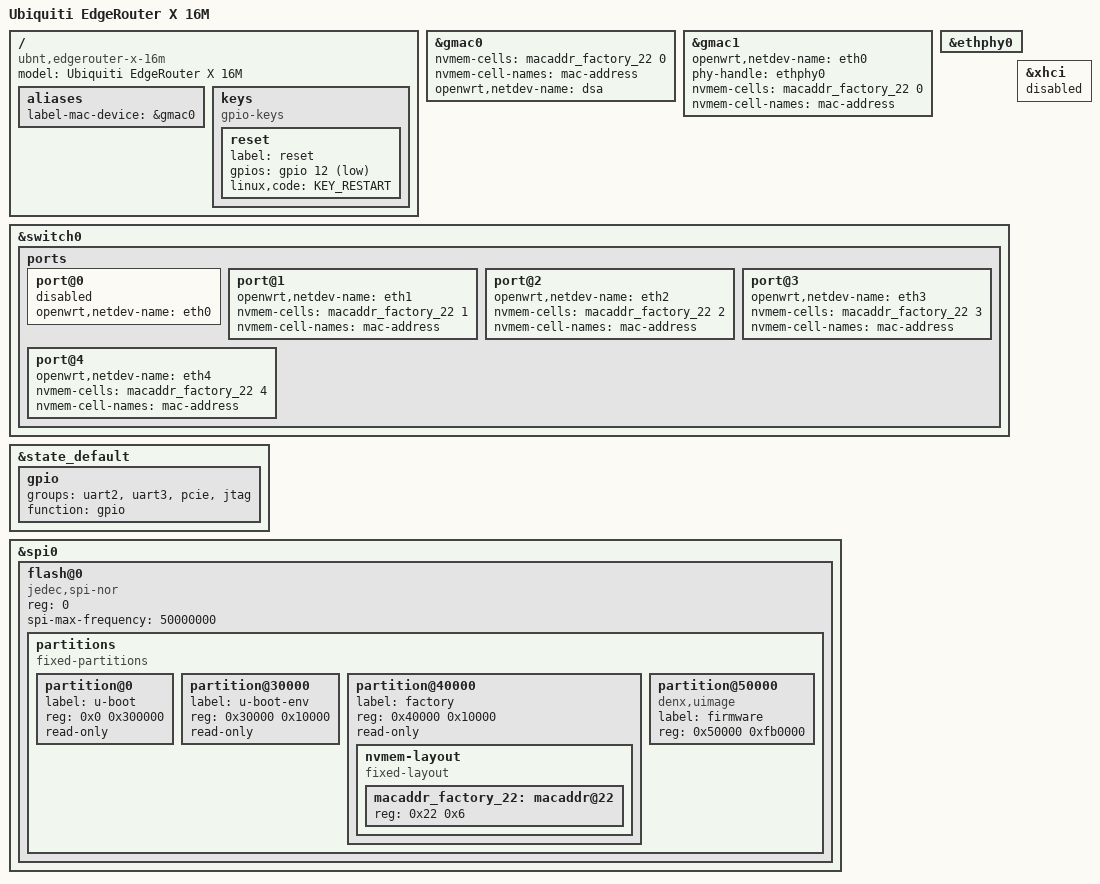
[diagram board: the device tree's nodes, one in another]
#include "mt7621.dtsi"

#include <dt-bindings/gpio/gpio.h>
#include <dt-bindings/input/input.h>

/ {
	model = "Ubiquiti EdgeRouter X 16M";
	compatible = "ubnt,edgerouter-x-16m", "mediatek,mt7621-soc";
};

/ {
	aliases {
		label-mac-device = &gmac0;
	};

	keys {
		compatible = "gpio-keys";

		reset {
			label = "reset";
			gpios = <&gpio 12 GPIO_ACTIVE_LOW>;
			linux,code = <KEY_RESTART>;
		};
	};
};

&gmac0 {
	nvmem-cells = <&macaddr_factory_22 0>;
	nvmem-cell-names = "mac-address";
	openwrt,netdev-name = "dsa";
};

&gmac1 {
	status = "okay";
	openwrt,netdev-name = "eth0";
	phy-handle = <&ethphy0>;

	nvmem-cells = <&macaddr_factory_22 0>;
	nvmem-cell-names = "mac-address";
};

&ethphy0 {
	/delete-property/ interrupts;
};

&switch0 {
	ports {
		port@0 {
			status = "disabled";
			openwrt,netdev-name = "eth0";
			/delete-property/ label;
		};

		port@1 {
			status = "okay";
			openwrt,netdev-name = "eth1";
			nvmem-cells = <&macaddr_factory_22 1>;
			nvmem-cell-names = "mac-address";
			/delete-property/ label;
		};

		port@2 {
			status = "okay";
			openwrt,netdev-name = "eth2";
			nvmem-cells = <&macaddr_factory_22 2>;
			nvmem-cell-names = "mac-address";
			/delete-property/ label;
		};

		port@3 {
			status = "okay";
			openwrt,netdev-name = "eth3";
			nvmem-cells = <&macaddr_factory_22 3>;
			nvmem-cell-names = "mac-address";
			/delete-property/ label;
		};

		port@4 {
			status = "okay";
			openwrt,netdev-name = "eth4";
			nvmem-cells = <&macaddr_factory_22 4>;
			nvmem-cell-names = "mac-address";
			/delete-property/ label;
		};
	};
};

&state_default {
	gpio {
		groups = "uart2", "uart3", "pcie", "jtag";
		function = "gpio";
	};
};

&spi0 {
	status = "okay";

	flash@0 {
		compatible = "jedec,spi-nor";
		reg = <0>;
		spi-max-frequency = <50000000>;

		partitions {
			compatible = "fixed-partitions";
			#address-cells = <1>;
			#size-cells = <1>;

			partition@0 {
				label = "u-boot";
				reg = <0x0 0x300000>;
				read-only;
			};
			
			partition@30000 {
				label = "u-boot-env";
				reg = <0x30000 0x10000>;
				read-only;
			};
			
			partition@40000 {
				label = "factory";
				reg = <0x40000 0x10000>;
				read-only;

				nvmem-layout {
					compatible = "fixed-layout";
					#address-cells = <1>;
					#size-cells = <1>;

					macaddr_factory_22: macaddr@22 {
						reg = <0x22 0x6>;
					};
				};
			};
			
			partition@50000 {
				compatible = "denx,uimage";
				label = "firmware";
				reg = <0x50000 0xfb0000>;
			};
		};
	};
};

&xhci {
	status = "disabled";
};
